AUTOSAR XML (schema 00046)
package /ComponentTypes
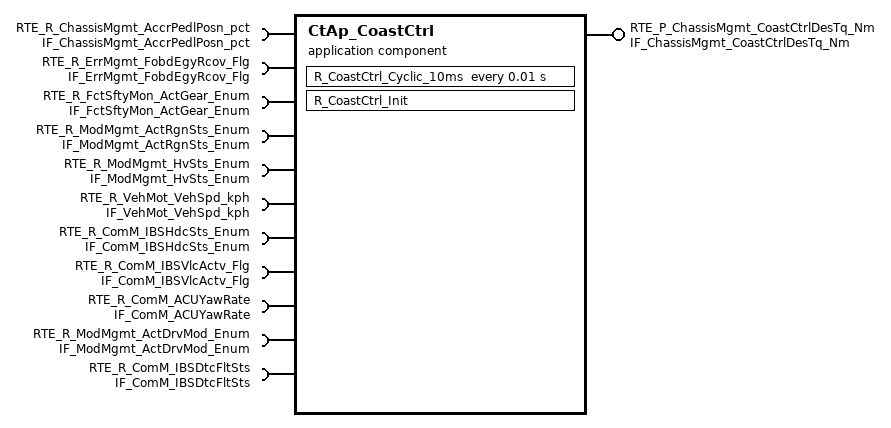
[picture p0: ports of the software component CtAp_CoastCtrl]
  application sw component type CtAp_CoastCtrl
    provide port RTE_P_ChassisMgmt_CoastCtrlDesTq_Nm: nonqueued-sender-com-spec{data-element=tec_ChassisMgmt_CoastCtrlDesTq_Nm, init-value=0}, provided-interface=IF_ChassisMgmt_CoastCtrlDesTq_Nm
    11 x require port:
      RTE_R_ChassisMgmt_AccrPedlPosn_pct: nonqueued-receiver-com-spec{data-element=tec_ChassisMgmt_AccrPedlPosn_pct, filter=data-filter-type=ALWAYS, init-value=0}, required-interface=IF_ChassisMgmt_AccrPedlPosn_pct
      RTE_R_ErrMgmt_FobdEgyRcov_Flg: nonqueued-receiver-com-spec{data-element=tec_ErrMgmt_FobdEgyRcov_Flg, filter=data-filter-type=ALWAYS, init-value=0}, required-interface=IF_ErrMgmt_FobdEgyRcov_Flg
      RTE_R_FctSftyMon_ActGear_Enum: nonqueued-receiver-com-spec{data-element=tec_FctSftyMon_ActGear_Enum, filter=data-filter-type=ALWAYS, init-value=0}, required-interface=IF_FctSftyMon_ActGear_Enum
      RTE_R_ModMgmt_ActRgnSts_Enum: nonqueued-receiver-com-spec{data-element=tec_ModMgmt_ActRgnSts_Enum, filter=data-filter-type=ALWAYS, init-value=0}, required-interface=IF_ModMgmt_ActRgnSts_Enum
      RTE_R_ModMgmt_HvSts_Enum: nonqueued-receiver-com-spec{data-element=tec_ModMgmt_HvSts_Enum, filter=data-filter-type=ALWAYS, init-value=0}, required-interface=IF_ModMgmt_HvSts_Enum
      RTE_R_VehMot_VehSpd_kph: nonqueued-receiver-com-spec{data-element=tec_VehMot_VehSpd_kph, filter=data-filter-type=ALWAYS, init-value=0}, required-interface=IF_VehMot_VehSpd_kph
      RTE_R_ComM_IBSHdcSts_Enum: nonqueued-receiver-com-spec{data-element=tec_ComM_IBSHdcSts_Enum, filter=data-filter-type=ALWAYS, init-value=0}, required-interface=IF_ComM_IBSHdcSts_Enum
      RTE_R_ComM_IBSVlcActv_Flg: nonqueued-receiver-com-spec{data-element=tec_ComM_IBSVlcActv_Flg, filter=data-filter-type=ALWAYS, init-value=0}, required-interface=IF_ComM_IBSVlcActv_Flg
      RTE_R_ComM_ACUYawRate: nonqueued-receiver-com-spec{data-element=tec_ComM_ACUYawRate, filter=data-filter-type=ALWAYS, init-value=0}, required-interface=IF_ComM_ACUYawRate
      RTE_R_ModMgmt_ActDrvMod_Enum: nonqueued-receiver-com-spec{data-element=tec_ModMgmt_ActDrvMod_Enum, filter=data-filter-type=ALWAYS, init-value=0}, required-interface=IF_ModMgmt_ActDrvMod_Enum
      RTE_R_ComM_IBSDtcFltSts: nonqueued-receiver-com-spec{data-element=tec_ComM_IBSDtcFltSts, filter=data-filter-type=ALWAYS, init-value=0}, required-interface=IF_ComM_IBSDtcFltSts
    behavior CtAp_CoastCtrl_InternalBehavior
      timing event TMT_R_CoastCtrl_Cyclic_10ms: start-on-event=R_CoastCtrl_Cyclic_10ms, period=0.01
      init event CtAp_CoastCtrl_InitEvent: start-on-event=R_CoastCtrl_Init
      runnable R_CoastCtrl_Cyclic_10ms
        data-receive-point-by-arguments:
          11 x access:
            REC_RTE_R_ChassisMgmt_AccrPedlPosn_pct_tec_ChassisMgmt_AccrPedlPosn_pct: accessed-variable=RTE_R_ChassisMgmt_AccrPedlPosn_pct.tec_ChassisMgmt_AccrPedlPosn_pct
            REC_RTE_R_ComM_IBSHdcSts_Enum_tec_ComM_IBSHdcSts_Enum: accessed-variable=RTE_R_ComM_IBSHdcSts_Enum.tec_ComM_IBSHdcSts_Enum
            REC_RTE_R_ErrMgmt_FobdEgyRcov_Flg_tec_ErrMgmt_FobdEgyRcov_Flg: accessed-variable=RTE_R_ErrMgmt_FobdEgyRcov_Flg.tec_ErrMgmt_FobdEgyRcov_Flg
            REC_RTE_R_FctSftyMon_ActGear_Enum_tec_FctSftyMon_ActGear_Enum: accessed-variable=RTE_R_FctSftyMon_ActGear_Enum.tec_FctSftyMon_ActGear_Enum
            REC_RTE_R_ModMgmt_ActRgnSts_Enum_tec_ModMgmt_ActRgnSts_Enum: accessed-variable=RTE_R_ModMgmt_ActRgnSts_Enum.tec_ModMgmt_ActRgnSts_Enum
            REC_RTE_R_ModMgmt_HvSts_Enum_tec_ModMgmt_HvSts_Enum: accessed-variable=RTE_R_ModMgmt_HvSts_Enum.tec_ModMgmt_HvSts_Enum
            REC_RTE_R_VehMot_VehSpd_kph_tec_VehMot_VehSpd_kph: accessed-variable=RTE_R_VehMot_VehSpd_kph.tec_VehMot_VehSpd_kph
            REC_RTE_R_ComM_IBSVlcActv_Flg_tec_ComM_IBSVlcActv_Flg: accessed-variable=RTE_R_ComM_IBSVlcActv_Flg.tec_ComM_IBSVlcActv_Flg
            REC_RTE_R_ComM_ACUYawRate_tec_ComM_ACUYawRate: accessed-variable=RTE_R_ComM_ACUYawRate.tec_ComM_ACUYawRate
            REC_RTE_R_ModMgmt_ActDrvMod_Enum_tec_ModMgmt_ActDrvMod_Enum: accessed-variable=RTE_R_ModMgmt_ActDrvMod_Enum.tec_ModMgmt_ActDrvMod_Enum
            REC_RTE_R_ComM_IBSDtcFltSts_tec_ComM_IBSDtcFltSts: accessed-variable=RTE_R_ComM_IBSDtcFltSts.tec_ComM_IBSDtcFltSts
        data-send-points:
          access SEND_RTE_P_ChassisMgmt_CoastCtrlDesTq_Nm_tec_ChassisMgmt_CoastCtrlDesTq_Nm: accessed-variable=RTE_P_ChassisMgmt_CoastCtrlDesTq_Nm.tec_ChassisMgmt_CoastCtrlDesTq_Nm
      runnable R_CoastCtrl_Init
  swc implementation CtAp_CoastCtrl_Implementation: behavior=CtAp_CoastCtrl_InternalBehavior
